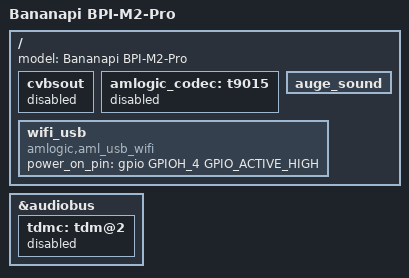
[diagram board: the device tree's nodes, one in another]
/*
 * arch/arm64/boot/dts/amlogic/meson64_odroidc4.dts
 *
 * Copyright (C) 2019 Hardkernel Co., Ltd. All rights reserved.
 *
 * This program is free software; you can redistribute it and/or modify
 * it under the terms of the GNU General Public License as published by
 * the Free Software Foundation; either version 2 of the License, or
 * (at your option) any later version.
 *
 * This program is distributed in the hope that it will be useful, but WITHOUT
 * ANY WARRANTY; without even the implied warranty of MERCHANTABILITY or
 * FITNESS FOR A PARTICULAR PURPOSE.  See the GNU General Public License for
 * more details.
 *
 */

/dts-v1/;

#include "meson64_bananapi_m5.dts"

/ {
	model = "Bananapi BPI-M2-Pro";

	cvbsout {
		status = "disabled";
	};

	amlogic_codec:t9015{
		status = "disabled";
	};

	auge_sound: auge_sound {
		/delete-node/ aml-audio-card,dai-link@1;
	};

	wifi_usb {
		compatible = "amlogic,aml_usb_wifi";
		status = "okay";
		power_on_pin = <&gpio   GPIOH_4         GPIO_ACTIVE_HIGH>;
	};

};

&audiobus {
	tdmc: tdm@2 {
		status = "disabled";
	};
};
